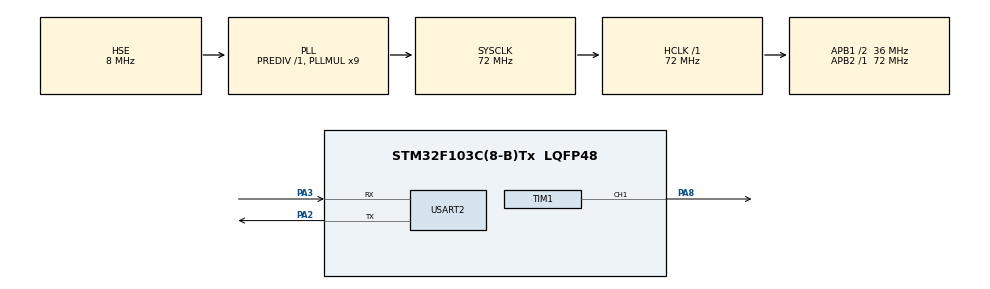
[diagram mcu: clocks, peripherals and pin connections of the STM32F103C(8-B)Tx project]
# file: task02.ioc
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Dma.Request0=USART2_RX
Dma.Request1=USART2_TX
Dma.USART2_RX.0.Direction=DMA_PERIPH_TO_MEMORY
Dma.USART2_RX.0.Instance=DMA1_Channel6
Dma.USART2_RX.0.MemDataAlignment=DMA_MDATAALIGN_BYTE
Dma.USART2_RX.0.MemInc=DMA_MINC_ENABLE
Dma.USART2_RX.0.Mode=DMA_NORMAL
Dma.USART2_RX.0.PeriphDataAlignment=DMA_PDATAALIGN_BYTE
Dma.USART2_RX.0.PeriphInc=DMA_PINC_DISABLE
Dma.USART2_RX.0.Priority=DMA_PRIORITY_LOW
Dma.USART2_TX.1.Direction=DMA_MEMORY_TO_PERIPH
Dma.USART2_TX.1.Instance=DMA1_Channel7
Dma.USART2_TX.1.MemDataAlignment=DMA_MDATAALIGN_BYTE
Dma.USART2_TX.1.MemInc=DMA_MINC_ENABLE
Dma.USART2_TX.1.Mode=DMA_NORMAL
Dma.USART2_TX.1.PeriphDataAlignment=DMA_PDATAALIGN_BYTE
Dma.USART2_TX.1.PeriphInc=DMA_PINC_DISABLE
Dma.USART2_TX.1.Priority=DMA_PRIORITY_LOW
Mcu.Family=STM32F1
Mcu.Name=STM32F103C(8-B)Tx
Mcu.Package=LQFP48
NVIC.DMA1_Channel6_IRQn=true\:0\:0\:false\:false\:true\:false\:true\:true
NVIC.DMA1_Channel7_IRQn=true\:0\:0\:false\:false\:true\:false\:true\:true
NVIC.PriorityGroup=NVIC_PRIORITYGROUP_4
NVIC.USART2_IRQn=true\:0\:0\:false\:false\:true\:false\:true\:true
PA13.Mode=Serial_Wire
PA13.Signal=SYS_JTMS-SWDIO
PA14.Mode=Serial_Wire
PA14.Signal=SYS_JTCK-SWCLK
PA2.Mode=Asynchronous
PA2.Signal=USART2_TX
PA3.Mode=Asynchronous
PA3.Signal=USART2_RX
PA8.Signal=S_TIM1_CH1
PD0-OSC_IN.Mode=HSE-External-Oscillator
PD0-OSC_IN.Signal=RCC_OSC_IN
PD1-OSC_OUT.Mode=HSE-External-Oscillator
PD1-OSC_OUT.Signal=RCC_OSC_OUT
ProjectManager.HeapSize=0x200
ProjectManager.StackSize=0x400
ProjectManager.TargetToolchain=CMake
RCC.AHBFreq_Value=72000000
RCC.APB1CLKDivider=RCC_HCLK_DIV2
RCC.APB1Freq_Value=36000000
RCC.APB1TimFreq_Value=72000000
RCC.APB2Freq_Value=72000000
RCC.APB2TimFreq_Value=72000000
RCC.HCLKFreq_Value=72000000
RCC.PLLMUL=RCC_PLL_MUL9
RCC.PLLSourceVirtual=RCC_PLLSOURCE_HSE
RCC.SYSCLKFreq_VALUE=72000000
RCC.SYSCLKSource=RCC_SYSCLKSOURCE_PLLCLK
RCC.USBFreq_Value=72000000
SH.S_TIM1_CH1.0=TIM1_CH1,PWM Generation1 CH1
TIM1.Channel-PWM\ Generation1\ CH1=TIM_CHANNEL_1
TIM1.Period=2000-1
TIM1.Prescaler=720-1
USART2.VirtualMode=VM_ASYNC
VP_TIM1_VS_ClockSourceINT.Mode=Internal
board=custom

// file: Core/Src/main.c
/* USER CODE BEGIN Header */
/**
  ******************************************************************************
  * @file           : main.c
  * @brief          : Main program body
  ******************************************************************************
  * @attention
  *
  * Copyright (c) 2025 STMicroelectronics.
  * All rights reserved.
  *
  * This software is licensed under terms that can be found in the LICENSE file
  * in the root directory of this software component.
  * If no LICENSE file comes with this software, it is provided AS-IS.
  *
  ******************************************************************************
  */
/* USER CODE END Header */
#include "main.h"
#include "stm32f1xx_hal_uart.h"
#include <stdint.h>

TIM_HandleTypeDef htim1;

UART_HandleTypeDef huart2;
DMA_HandleTypeDef hdma_usart2_rx;
DMA_HandleTypeDef hdma_usart2_tx;

/* USER CODE BEGIN PV */
uint8_t Receivedata[3];
int angel = 0;
int a;
int b;
int c;
int ccr;
uint8_t len;

/* USER CODE END PV */

void SystemClock_Config(void);
static void MX_GPIO_Init(void);
static void MX_DMA_Init(void);
static void MX_TIM1_Init(void);
static void MX_USART2_UART_Init(void);

/* USER CODE BEGIN 0 */

void zhan (uint8_t *data)
{
  a = (data[0]-'0')*100;
  b = (data[1]-'0')*10;
  c = (data[2]-'0')*1;
  angel = a + b + c;
  ccr=(angel*10/9)+50;
  __HAL_TIM_SET_COMPARE(&htim1, TIM_CHANNEL_1, ccr);
}
void HAL_UART_RxCpltCallback(UART_HandleTypeDef *huart)
{
    HAL_UART_Transmit_DMA(&huart2, Receivedata, sizeof(Receivedata));
    zhan(Receivedata);
    HAL_UART_Receive_DMA(&huart2, Receivedata, sizeof(Receivedata));

}
/* USER CODE END 0 */

int main(void)
{

  /* MCU Configuration--------------------------------------------------------*/

  /* Reset of all peripherals, Initializes the Flash interface and the Systick. */
  HAL_Init();

  /* Configure the system clock */
  SystemClock_Config();

  /* Initialize all configured peripherals */
  MX_GPIO_Init();
  MX_DMA_Init();
  MX_TIM1_Init();
  MX_USART2_UART_Init();
  /* USER CODE BEGIN 2 */
  HAL_TIM_PWM_Start(&htim1, TIM_CHANNEL_1);
  HAL_UART_Receive_DMA(&huart2, Receivedata, sizeof(Receivedata));
  /* USER CODE END 2 */

  /* Infinite loop */
  while (1)
  {

  }
}

void SystemClock_Config(void)
{
  RCC_OscInitTypeDef RCC_OscInitStruct = {0};
  RCC_ClkInitTypeDef RCC_ClkInitStruct = {0};

  /** Initializes the RCC Oscillators according to the specified parameters
  * in the RCC_OscInitTypeDef structure.
  */
  RCC_OscInitStruct.OscillatorType = RCC_OSCILLATORTYPE_HSE;
  RCC_OscInitStruct.HSEState = RCC_HSE_ON;
  RCC_OscInitStruct.HSEPredivValue = RCC_HSE_PREDIV_DIV1;
  RCC_OscInitStruct.HSIState = RCC_HSI_ON;
  RCC_OscInitStruct.PLL.PLLState = RCC_PLL_ON;
  RCC_OscInitStruct.PLL.PLLSource = RCC_PLLSOURCE_HSE;
  RCC_OscInitStruct.PLL.PLLMUL = RCC_PLL_MUL9;
  if (HAL_RCC_OscConfig(&RCC_OscInitStruct) != HAL_OK)
  {
    Error_Handler();
  }

  /** Initializes the CPU, AHB and APB buses clocks
  */
  RCC_ClkInitStruct.ClockType = RCC_CLOCKTYPE_HCLK|RCC_CLOCKTYPE_SYSCLK
                              |RCC_CLOCKTYPE_PCLK1|RCC_CLOCKTYPE_PCLK2;
  RCC_ClkInitStruct.SYSCLKSource = RCC_SYSCLKSOURCE_PLLCLK;
  RCC_ClkInitStruct.AHBCLKDivider = RCC_SYSCLK_DIV1;
  RCC_ClkInitStruct.APB1CLKDivider = RCC_HCLK_DIV2;
  RCC_ClkInitStruct.APB2CLKDivider = RCC_HCLK_DIV1;

  if (HAL_RCC_ClockConfig(&RCC_ClkInitStruct, FLASH_LATENCY_2) != HAL_OK)
  {
    Error_Handler();
  }
}

static void MX_TIM1_Init(void)
{

  TIM_ClockConfigTypeDef sClockSourceConfig = {0};
  TIM_MasterConfigTypeDef sMasterConfig = {0};
  TIM_OC_InitTypeDef sConfigOC = {0};
  TIM_BreakDeadTimeConfigTypeDef sBreakDeadTimeConfig = {0};

  htim1.Instance = TIM1;
  htim1.Init.Prescaler = 720-1;
  htim1.Init.CounterMode = TIM_COUNTERMODE_UP;
  htim1.Init.Period = 2000-1;
  htim1.Init.ClockDivision = TIM_CLOCKDIVISION_DIV1;
  htim1.Init.RepetitionCounter = 0;
  htim1.Init.AutoReloadPreload = TIM_AUTORELOAD_PRELOAD_DISABLE;
  if (HAL_TIM_Base_Init(&htim1) != HAL_OK)
  {
    Error_Handler();
  }
  sClockSourceConfig.ClockSource = TIM_CLOCKSOURCE_INTERNAL;
  if (HAL_TIM_ConfigClockSource(&htim1, &sClockSourceConfig) != HAL_OK)
  {
    Error_Handler();
  }
  if (HAL_TIM_PWM_Init(&htim1) != HAL_OK)
  {
    Error_Handler();
  }
  sMasterConfig.MasterOutputTrigger = TIM_TRGO_RESET;
  sMasterConfig.MasterSlaveMode = TIM_MASTERSLAVEMODE_DISABLE;
  if (HAL_TIMEx_MasterConfigSynchronization(&htim1, &sMasterConfig) != HAL_OK)
  {
    Error_Handler();
  }
  sConfigOC.OCMode = TIM_OCMODE_PWM1;
  sConfigOC.Pulse = 0;
  sConfigOC.OCPolarity = TIM_OCPOLARITY_HIGH;
  sConfigOC.OCNPolarity = TIM_OCNPOLARITY_HIGH;
  sConfigOC.OCFastMode = TIM_OCFAST_DISABLE;
  sConfigOC.OCIdleState = TIM_OCIDLESTATE_RESET;
  sConfigOC.OCNIdleState = TIM_OCNIDLESTATE_RESET;
  if (HAL_TIM_PWM_ConfigChannel(&htim1, &sConfigOC, TIM_CHANNEL_1) != HAL_OK)
  {
    Error_Handler();
  }
  sBreakDeadTimeConfig.OffStateRunMode = TIM_OSSR_DISABLE;
  sBreakDeadTimeConfig.OffStateIDLEMode = TIM_OSSI_DISABLE;
  sBreakDeadTimeConfig.LockLevel = TIM_LOCKLEVEL_OFF;
  sBreakDeadTimeConfig.DeadTime = 0;
  sBreakDeadTimeConfig.BreakState = TIM_BREAK_DISABLE;
  sBreakDeadTimeConfig.BreakPolarity = TIM_BREAKPOLARITY_HIGH;
  sBreakDeadTimeConfig.AutomaticOutput = TIM_AUTOMATICOUTPUT_DISABLE;
  if (HAL_TIMEx_ConfigBreakDeadTime(&htim1, &sBreakDeadTimeConfig) != HAL_OK)
  {
    Error_Handler();
  }
  HAL_TIM_MspPostInit(&htim1);

}

static void MX_USART2_UART_Init(void)
{

  huart2.Instance = USART2;
  huart2.Init.BaudRate = 115200;
  huart2.Init.WordLength = UART_WORDLENGTH_8B;
  huart2.Init.StopBits = UART_STOPBITS_1;
  huart2.Init.Parity = UART_PARITY_NONE;
  huart2.Init.Mode = UART_MODE_TX_RX;
  huart2.Init.HwFlowCtl = UART_HWCONTROL_NONE;
  huart2.Init.OverSampling = UART_OVERSAMPLING_16;
  if (HAL_UART_Init(&huart2) != HAL_OK)
  {
    Error_Handler();
  }

}

static void MX_DMA_Init(void)
{

  /* DMA controller clock enable */
  __HAL_RCC_DMA1_CLK_ENABLE();

  /* DMA interrupt init */
  /* DMA1_Channel6_IRQn interrupt configuration */
  HAL_NVIC_SetPriority(DMA1_Channel6_IRQn, 0, 0);
  HAL_NVIC_EnableIRQ(DMA1_Channel6_IRQn);
  /* DMA1_Channel7_IRQn interrupt configuration */
  HAL_NVIC_SetPriority(DMA1_Channel7_IRQn, 0, 0);
  HAL_NVIC_EnableIRQ(DMA1_Channel7_IRQn);

}

static void MX_GPIO_Init(void)
{

  /* GPIO Ports Clock Enable */
  __HAL_RCC_GPIOD_CLK_ENABLE();
  __HAL_RCC_GPIOA_CLK_ENABLE();

}

void Error_Handler(void)
{
  __disable_irq();
  while (1)
  {
  }
}
